# S6E1C1xB register map
Vendor: Cypress; File version: 2.1
CPU: CM0PLUS r0p1, little endian, no MPU, no FPU, 2 interrupt priority bits
Registers are 32-bit, read-write, reset 0x0 unless marked. A register's access mark holds for its fields unless they carry their own. Offsets are from the block's base; [hi:lo] are bit positions; {n}, {i} and the like mark numbered series.

## EXTI — External Interrupt and NMI Control
Base 0x40030000
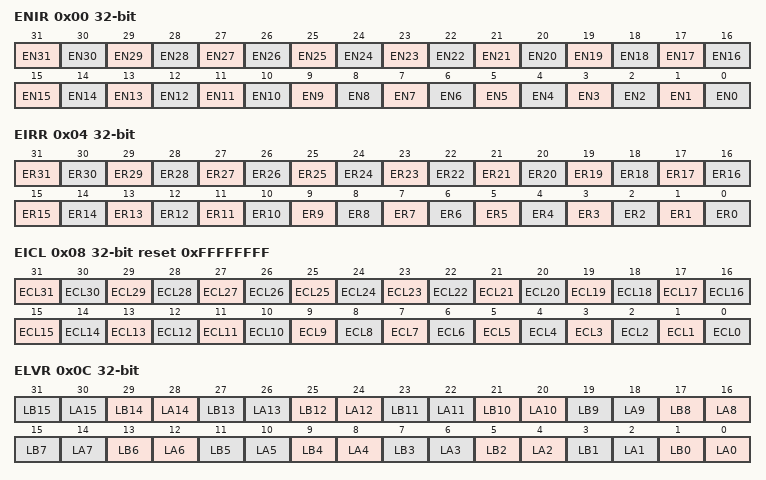
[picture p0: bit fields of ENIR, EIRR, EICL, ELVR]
0x00 ENIR — External Interrupt Enable Register [BHW]
  [31] EN31 — External interrupt Ch.31 enable bit
  [30] EN30 — External interrupt Ch.30 enable bit
  [29] EN29 — External interrupt Ch.29 enable bit
  [28] EN28 — External interrupt Ch.28 enable bit
  [27] EN27 — External interrupt Ch.27 enable bit
  [26] EN26 — External interrupt Ch.26 enable bit
  [25] EN25 — External interrupt Ch.25 enable bit
  [24] EN24 — External interrupt Ch.24 enable bit
  [23] EN23 — External interrupt Ch.23 enable bit
  [22] EN22 — External interrupt Ch.22 enable bit
  [21] EN21 — External interrupt Ch.21 enable bit
  [20] EN20 — External interrupt Ch.20 enable bit
  [19] EN19 — External interrupt Ch.19 enable bit
  [18] EN18 — External interrupt Ch.18 enable bit
  [17] EN17 — External interrupt Ch.17 enable bit
  [16] EN16 — External interrupt Ch.16 enable bit
  [15] EN15 — External interrupt Ch.15 enable bit
  [14] EN14 — External interrupt Ch.14 enable bit
  [13] EN13 — External interrupt Ch.13 enable bit
  [12] EN12 — External interrupt Ch.12 enable bit
  [11] EN11 — External interrupt Ch.11 enable bit
  [10] EN10 — External interrupt Ch.10 enable bit
  [9] EN9 — External interrupt Ch.9 enable bit
  [8] EN8 — External interrupt Ch.8 enable bit
  [7] EN7 — External interrupt Ch.7 enable bit
  [6] EN6 — External interrupt Ch.6 enable bit
  [5] EN5 — External interrupt Ch.5 enable bit
  [4] EN4 — External interrupt Ch.4 enable bit
  [3] EN3 — External interrupt Ch.3 enable bit
  [2] EN2 — External interrupt Ch.2 enable bit
  [1] EN1 — External interrupt Ch.1 enable bit
  [0] EN0 — External interrupt Ch.0 enable bit
0x04 EIRR ro reset not defined — External Interrupt Factor Register [BHW]
  [31] ER31 — External interrupt Ch.31 request detection bit
  [30] ER30 — External interrupt Ch.30 request detection bit
  [29] ER29 — External interrupt Ch.29 request detection bit
  [28] ER28 — External interrupt Ch.28 request detection bit
  [27] ER27 — External interrupt Ch.27 request detection bit
  [26] ER26 — External interrupt Ch.26 request detection bit
  [25] ER25 — External interrupt Ch.25 request detection bit
  [24] ER24 — External interrupt Ch.24 request detection bit
  [23] ER23 — External interrupt Ch.23 request detection bit
  [22] ER22 — External interrupt Ch.22 request detection bit
  [21] ER21 — External interrupt Ch.21 request detection bit
  [20] ER20 — External interrupt Ch.20 request detection bit
  [19] ER19 — External interrupt Ch.19 request detection bit
  [18] ER18 — External interrupt Ch.18 request detection bit
  [17] ER17 — External interrupt Ch.17 request detection bit
  [16] ER16 — External interrupt Ch.16 request detection bit
  [15] ER15 — External interrupt Ch.15 request detection bit
  [14] ER14 — External interrupt Ch.14 request detection bit
  [13] ER13 — External interrupt Ch.13 request detection bit
  [12] ER12 — External interrupt Ch.12 request detection bit
  [11] ER11 — External interrupt Ch.11 request detection bit
  [10] ER10 — External interrupt Ch.10 request detection bit
  [9] ER9 — External interrupt Ch.9 request detection bit
  [8] ER8 — External interrupt Ch.8 request detection bit
  [7] ER7 — External interrupt Ch.7 request detection bit
  [6] ER6 — External interrupt Ch.6 request detection bit
  [5] ER5 — External interrupt Ch.5 request detection bit
  [4] ER4 — External interrupt Ch.4 request detection bit
  [3] ER3 — External interrupt Ch.3 request detection bit
  [2] ER2 — External interrupt Ch.2 request detection bit
  [1] ER1 — External interrupt Ch.1 request detection bit
  [0] ER0 — External interrupt Ch.0 request detection bit
0x08 EICL reset 0xFFFFFFFF — External Interrupt Factor Clear Register [BHW]
  [31] ECL31 — External interrupt Ch.31 factor clear bit
  [30] ECL30 — External interrupt Ch.30 factor clear bit
  [29] ECL29 — External interrupt Ch.29 factor clear bit
  [28] ECL28 — External interrupt Ch.28 factor clear bit
  [27] ECL27 — External interrupt Ch.27 factor clear bit
  [26] ECL26 — External interrupt Ch.26 factor clear bit
  [25] ECL25 — External interrupt Ch.25 factor clear bit
  [24] ECL24 — External interrupt Ch.24 factor clear bit
  [23] ECL23 — External interrupt Ch.23 factor clear bit
  [22] ECL22 — External interrupt Ch.22 factor clear bit
  [21] ECL21 — External interrupt Ch.21 factor clear bit
  [20] ECL20 — External interrupt Ch.20 factor clear bit
  [19] ECL19 — External interrupt Ch.19 factor clear bit
  [18] ECL18 — External interrupt Ch.18 factor clear bit
  [17] ECL17 — External interrupt Ch.17 factor clear bit
  [16] ECL16 — External interrupt Ch.16 factor clear bit
  [15] ECL15 — External interrupt Ch.15 factor clear bit
  [14] ECL14 — External interrupt Ch.14 factor clear bit
  [13] ECL13 — External interrupt Ch.13 factor clear bit
  [12] ECL12 — External interrupt Ch.12 factor clear bit
  [11] ECL11 — External interrupt Ch.11 factor clear bit
  [10] ECL10 — External interrupt Ch.10 factor clear bit
  [9] ECL9 — External interrupt Ch.9 factor clear bit
  [8] ECL8 — External interrupt Ch.8 factor clear bit
  [7] ECL7 — External interrupt Ch.7 factor clear bit
  [6] ECL6 — External interrupt Ch.6 factor clear bit
  [5] ECL5 — External interrupt Ch.5 factor clear bit
  [4] ECL4 — External interrupt Ch.4 factor clear bit
  [3] ECL3 — External interrupt Ch.3 factor clear bit
  [2] ECL2 — External interrupt Ch.2 factor clear bit
  [1] ECL1 — External interrupt Ch.1 factor clear bit
  [0] ECL0 — External interrupt Ch.0 factor clear bit
0x0C ELVR — External Interrupt Factor Level Register [BHW]
  [2n+1] LB{n} (n=0..15) — External interrupt request detection level selection bit for INT{n}
  [2n] LA{n} (n=0..15) — External interrupt request detection level selection bit for INT{n}
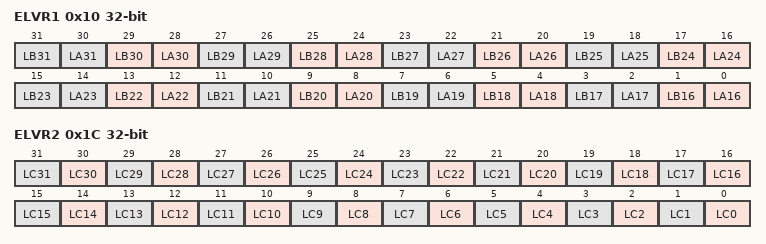
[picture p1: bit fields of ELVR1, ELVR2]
0x10 ELVR1 — External Interrupt Factor Level Register 1 [BHW]
  [2n-31] LB{n} (n=16..31) — External interrupt request detection level selection bit for INT{n}
  [2n-32] LA{n} (n=16..31) — External interrupt request detection level selection bit for INT{n}
0x14 NMIRR 16-bit ro — Non Maskable Interrupt Factor Register [BHW]
  [0] NR — NMI interrupt request detection bit
0x18 NMICL 16-bit reset 0x1 — Non Maskable Interrupt Factor Clear Register [BHW]
  [0] NCL — NMI interrupt factor clear bit
0x1C ELVR2 — External Interrupt Factor Level Register 2 [BHW]
  [n] LC{n} (n=0..31) — External interrupt request detection level selection bit for INT{n}
0x20 NMIENR 8-bit — Non Maskable Interrupt Enable Register [BHW]
  [0] NE0 — NMI enable bit

## Notices in the file
Copyright (C) 2013-2016, Cypress Semiconductor Corporation or a
subsidiary of Cypress Semiconductor Corporation.  All rights reserved.
This software, including source code, documentation and related
materials ("Software"), is owned by Cypress Semiconductor Corporation or
one of its subsidiaries ("Cypress") and is protected by and subject to
worldwide patent protection (United States and foreign), United States
copyright laws and international treaty provisions. Therefore, you may use
this Software only as provided in the license agreement accompanying the
software package from which you obtained this Software ("EULA").
If no EULA applies, Cypress hereby grants you a personal, non-exclusive,
non-transferable license to copy, modify, and compile the
Software source code solely for use in connection with Cypress's
integrated circuit products.  Any reproduction, modification, translation,
compilation, or representation of this Software except as specified
above is prohibited without the express written permission of Cypress.
Disclaimer: THIS SOFTWARE IS PROVIDED AS-IS, WITH NO
WARRANTY OF ANY KIND, EXPRESS OR IMPLIED, INCLUDING,
BUT NOT LIMITED TO, NONINFRINGEMENT, IMPLIED
WARRANTIES OF MERCHANTABILITY AND FITNESS FOR A
PARTICULAR PURPOSE. Cypress reserves the right to make
changes to the Software without notice. Cypress does not assume any
liability arising out of the application or use of the Software or any
product or circuit described in the Software. Cypress does not
authorize its products for use in any products where a malfunction or
failure of the Cypress product may reasonably be expected to result in
significant property damage, injury or death ("High Risk Product"). By
including Cypress's product in a High Risk Product, the manufacturer
of such system or application assumes all risk of such use and in doing
so agrees to indemnify Cypress against all liability.
